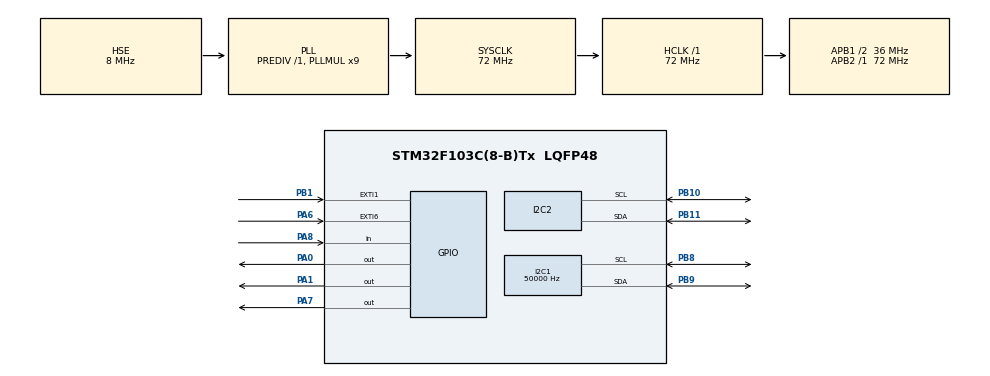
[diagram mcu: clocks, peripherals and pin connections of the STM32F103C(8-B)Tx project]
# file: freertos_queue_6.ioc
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FREERTOS.Tasks01=my_maintask,24,128,StartDefaultTask,Default,NULL,Dynamic,NULL,NULL
FREERTOS.configTOTAL_HEAP_SIZE=6144
I2C1.ClockSpeed=50000
I2C1.DualAddressMode=I2C_DUALADDRESS_DISABLE
I2C1.GeneralCallMode=I2C_GENERALCALL_DISABLE
I2C1.I2C_Mode=I2C_Standard
I2C1.NoStretchMode=I2C_NOSTRETCH_DISABLE
Mcu.Family=STM32F1
Mcu.Name=STM32F103C(8-B)Tx
Mcu.Package=LQFP48
NVIC.EXTI1_IRQn=true\:5\:0\:false\:false\:true\:true\:true\:true\:true
NVIC.EXTI9_5_IRQn=true\:5\:0\:false\:false\:true\:true\:true\:true\:true
NVIC.PriorityGroup=NVIC_PRIORITYGROUP_4
NVIC.TIM1_UP_IRQn=true\:5\:0\:false\:false\:true\:true\:true\:true\:true
NVIC.TIM2_IRQn=true\:5\:0\:false\:false\:true\:true\:true\:true\:true
NVIC.TIM4_IRQn=true\:15\:0\:false\:false\:true\:false\:false\:true\:true
NVIC.TimeBase=TIM4_IRQn
NVIC.TimeBaseIP=TIM4
PA0-WKUP.GPIO_ModeDefaultOutputPP=GPIO_MODE_OUTPUT_PP
PA0-WKUP.GPIO_PuPd=GPIO_PULLUP
PA0-WKUP.Signal=GPIO_Output
PA1.GPIO_PuPd=GPIO_PULLUP
PA1.Signal=GPIO_Output
PA13.Mode=Serial_Wire
PA13.Signal=SYS_JTMS-SWDIO
PA14.Mode=Serial_Wire
PA14.Signal=SYS_JTCK-SWCLK
PA6.Signal=GPXTI6
PA7.GPIO_PuPd=GPIO_PULLUP
PA7.PinState=GPIO_PIN_RESET
PA7.Signal=GPIO_Output
PA8.Signal=GPIO_Input
PB1.GPIO_ModeDefaultEXTI=GPIO_MODE_IT_RISING_FALLING
PB1.Signal=GPXTI1
PB10.Mode=I2C
PB10.Signal=I2C2_SCL
PB11.Mode=I2C
PB11.Signal=I2C2_SDA
PB8.Mode=I2C
PB8.Signal=I2C1_SCL
PB9.Mode=I2C
PB9.Signal=I2C1_SDA
PD0-OSC_IN.Mode=HSE-External-Oscillator
PD0-OSC_IN.Signal=RCC_OSC_IN
PD1-OSC_OUT.Mode=HSE-External-Oscillator
PD1-OSC_OUT.Signal=RCC_OSC_OUT
ProjectManager.HeapSize=0x200
ProjectManager.StackSize=0x400
ProjectManager.TargetToolchain=MDK-ARM V5.32
RCC.AHBFreq_Value=72000000
RCC.APB1CLKDivider=RCC_HCLK_DIV2
RCC.APB1Freq_Value=36000000
RCC.APB1TimFreq_Value=72000000
RCC.APB2Freq_Value=72000000
RCC.APB2TimFreq_Value=72000000
RCC.HCLKFreq_Value=72000000
RCC.PLLMUL=RCC_PLL_MUL9
RCC.PLLSourceVirtual=RCC_PLLSOURCE_HSE
RCC.SYSCLKFreq_VALUE=72000000
RCC.SYSCLKSource=RCC_SYSCLKSOURCE_PLLCLK
RCC.USBFreq_Value=72000000
TIM2.AutoReloadPreload=TIM_AUTORELOAD_PRELOAD_DISABLE
TIM3.TIM_MasterOutputTrigger=TIM_TRGO_RESET
VP_FREERTOS_VS_CMSIS_V2.Mode=CMSIS_V2
VP_SYS_VS_tim4.Mode=TIM4
VP_TIM1_VS_ClockSourceINT.Mode=Internal
VP_TIM2_VS_ClockSourceINT.Mode=Internal
VP_TIM3_VS_ClockSourceINT.Mode=Internal
board=custom

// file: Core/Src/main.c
/* USER CODE BEGIN Header */
/**
  ******************************************************************************
  * @file           : main.c
  * @brief          : Main program body
  ******************************************************************************
  * @attention
  *
  * Copyright (c) 2023 STMicroelectronics.
  * All rights reserved.
  *
  * This software is licensed under terms that can be found in the LICENSE file
  * in the root directory of this software component.
  * If no LICENSE file comes with this software, it is provided AS-IS.
  *
  ******************************************************************************
  */
/* USER CODE END Header */
#include "main.h"
#include "cmsis_os.h"
#include "i2c.h"
#include "tim.h"
#include "gpio.h"

/* USER CODE BEGIN PV */
extern void TIMDrvIrq(TIM_HandleTypeDef *htim);
/* USER CODE END PV */

void SystemClock_Config(void);
void MX_FREERTOS_Init(void);

int main(void)
{

  /* MCU Configuration--------------------------------------------------------*/

  /* Reset of all peripherals, Initializes the Flash interface and the Systick. */
  HAL_Init();

  /* Configure the system clock */
  SystemClock_Config();

  /* Initialize all configured peripherals */
  MX_GPIO_Init();
  MX_I2C1_Init();
  MX_TIM2_Init();
  MX_TIM3_Init();
  MX_TIM1_Init();
  MX_I2C2_Init();

  /* Init scheduler */
  osKernelInitialize();  /* Call init function for freertos objects (in freertos.c) */
  MX_FREERTOS_Init();

  /* Start scheduler */
  osKernelStart();

  /* We should never get here as control is now taken by the scheduler */
  /* Infinite loop */
  while (1)
  {

  }
}

void SystemClock_Config(void)
{
  RCC_OscInitTypeDef RCC_OscInitStruct = {0};
  RCC_ClkInitTypeDef RCC_ClkInitStruct = {0};

  /** Initializes the RCC Oscillators according to the specified parameters
  * in the RCC_OscInitTypeDef structure.
  */
  RCC_OscInitStruct.OscillatorType = RCC_OSCILLATORTYPE_HSE;
  RCC_OscInitStruct.HSEState = RCC_HSE_ON;
  RCC_OscInitStruct.HSEPredivValue = RCC_HSE_PREDIV_DIV1;
  RCC_OscInitStruct.HSIState = RCC_HSI_ON;
  RCC_OscInitStruct.PLL.PLLState = RCC_PLL_ON;
  RCC_OscInitStruct.PLL.PLLSource = RCC_PLLSOURCE_HSE;
  RCC_OscInitStruct.PLL.PLLMUL = RCC_PLL_MUL9;
  if (HAL_RCC_OscConfig(&RCC_OscInitStruct) != HAL_OK)
  {
    Error_Handler();
  }

  /** Initializes the CPU, AHB and APB buses clocks
  */
  RCC_ClkInitStruct.ClockType = RCC_CLOCKTYPE_HCLK|RCC_CLOCKTYPE_SYSCLK
                              |RCC_CLOCKTYPE_PCLK1|RCC_CLOCKTYPE_PCLK2;
  RCC_ClkInitStruct.SYSCLKSource = RCC_SYSCLKSOURCE_PLLCLK;
  RCC_ClkInitStruct.AHBCLKDivider = RCC_SYSCLK_DIV1;
  RCC_ClkInitStruct.APB1CLKDivider = RCC_HCLK_DIV2;
  RCC_ClkInitStruct.APB2CLKDivider = RCC_HCLK_DIV1;

  if (HAL_RCC_ClockConfig(&RCC_ClkInitStruct, FLASH_LATENCY_2) != HAL_OK)
  {
    Error_Handler();
  }
}

void HAL_TIM_PeriodElapsedCallback(TIM_HandleTypeDef *htim)
{
  /* USER CODE BEGIN Callback 0 */
    TIMDrvIrq(htim);
  /* USER CODE END Callback 0 */
  if (htim->Instance == TIM4) {
    HAL_IncTick();
  }
}

void Error_Handler(void)
{
  __disable_irq();
  while (1)
  {
  }
}

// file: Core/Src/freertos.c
/* USER CODE BEGIN Header */
/**
  ******************************************************************************
  * File Name          : freertos.c
  * Description        : Code for freertos applications
  ******************************************************************************
  * @attention
  *
  * Copyright (c) 2023 STMicroelectronics.
  * All rights reserved.
  *
  * This software is licensed under terms that can be found in the LICENSE file
  * in the root directory of this software component.
  * If no LICENSE file comes with this software, it is provided AS-IS.
  *
  ******************************************************************************
  */
/* USER CODE END Header */

#include "FreeRTOS.h"
#include "task.h"
#include "main.h"
#include "cmsis_os.h"

/* Definitions for my_maintask */
osThreadId_t my_maintaskHandle;
const osThreadAttr_t my_maintask_attributes = {
  .name = "my_maintask",
  .stack_size = 128 * 4,
  .priority = (osPriority_t) osPriorityNormal,
};

/* USER CODE BEGIN FunctionPrototypes */
extern void game1_test(void);
/* USER CODE END FunctionPrototypes */

void StartDefaultTask(void *argument);

void MX_FREERTOS_Init(void); /* (MISRA C 2004 rule 8.1) */

void MX_FREERTOS_Init(void) {

  /* Create the thread(s) */
  /* creation of my_maintask */
  my_maintaskHandle = osThreadNew(StartDefaultTask, NULL, &my_maintask_attributes);

  /* USER CODE BEGIN RTOS_THREADS */
  game1_test();
  /* add threads, ... */
  /* USER CODE END RTOS_THREADS */

}

void StartDefaultTask(void *argument)
{
  for(;;)
  {
    osDelay(1);
  }
}
